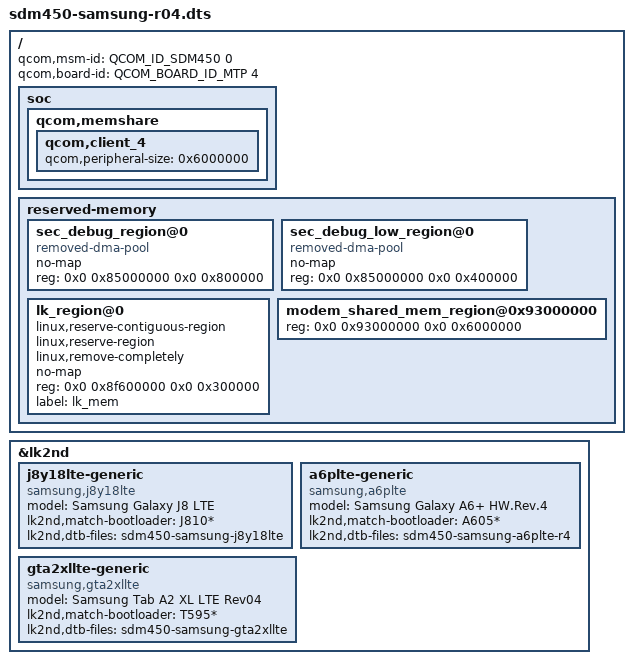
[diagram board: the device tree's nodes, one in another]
// SPDX-License-Identifier: GPL-2.0-only

/dts-v1/;

#include <skeleton64.dtsi>
#include <lk2nd.dtsi>

/ {
	qcom,msm-id = <QCOM_ID_SDM450 0>;
	qcom,board-id = <QCOM_BOARD_ID_MTP 4>;

	/* bootloader refuses the dtb if it cannot delete some nodes. */
	soc {
		#address-cells = <1>;
		#size-cells = <1>;
		ranges = <0x0 0x0 0x0 0xffffffff>;

		qcom,memshare {
			qcom,client_4 {
				qcom,peripheral-size = <0x6000000>;
			};
		};
	};

	reserved-memory {
		#address-cells = <2>;
		#size-cells = <2>;
		ranges;

		sec_debug_region@0 {
			compatible = "removed-dma-pool";
			no-map;
			reg = <0x0 0x85000000 0x0 0x800000>;
		};

		sec_debug_low_region@0 {
			compatible = "removed-dma-pool";
			no-map;
			reg = <0x0 0x85000000 0x0 0x400000>;
		};

		lk_region@0 {
			linux,reserve-contiguous-region;
			linux,reserve-region;
			linux,remove-completely;
			no-map;
			reg = <0x0 0x8f600000 0x0 0x300000>;
			label = "lk_mem";
		};

		modem_shared_mem_region@0x93000000 {
			reg = <0x0 0x93000000 0x0 0x6000000>;
		};
	};
};

&lk2nd {
	j8y18lte-generic {
		model = "Samsung Galaxy J8 LTE";
		compatible = "samsung,j8y18lte";
		lk2nd,match-bootloader = "J810*";

		lk2nd,dtb-files = "sdm450-samsung-j8y18lte";
	};

	a6plte-generic {
		model = "Samsung Galaxy A6+ HW.Rev.4";
		compatible = "samsung,a6plte";
		lk2nd,match-bootloader = "A605*";

		lk2nd,dtb-files = "sdm450-samsung-a6plte-r4";
	};

	gta2xllte-generic {
		model = "Samsung Tab A2 XL LTE Rev04";
		compatible = "samsung,gta2xllte";
		lk2nd,match-bootloader = "T595*";

		lk2nd,dtb-files = "sdm450-samsung-gta2xllte";
	};
};
